AUTOSAR XML (schema 4.0)
package /S02CONN/If
  sender receiver interface RemoteSvc
    data val
  sender receiver interface UdsDiag
    data val
package /S02CONN/Swc
  application sw component type TelematicsUnit
    provide port tcuToGwOut: provided-interface=RemoteSvc
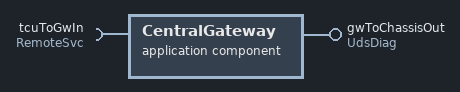
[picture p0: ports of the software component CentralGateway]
  application sw component type CentralGateway
    provide port gwToChassisOut: provided-interface=UdsDiag
    require port tcuToGwIn: required-interface=RemoteSvc
  application sw component type ChassisCtrl
    require port gwToChassisIn: required-interface=UdsDiag
  composition sw component type Root
    component tcu: type=TelematicsUnit
    component cgw: type=CentralGateway
    component chassis: type=ChassisCtrl
    connect tcu.tcuToGwOut -> cgw.tcuToGwIn
    connect cgw.gwToChassisOut -> chassis.gwToChassisIn
package /S02CONN/Comm
  pdu tcuToGwIPdu
    signal tcuToGwISig: system signal tcuToGwSSig
  secured i pdu tcuToGwSecuredIPdu: auth-info-tx-length=32, freshness-value-id=1, freshness-value-length=8, payload=tcuToGwIPdu
  pdu gwToChassisIPdu
    signal gwToChassisISig: system signal gwToChassisSSig
package /S02CONN/Topology
  ecu instance ChassisEcu
  ecu instance GatewayEcu
  ecu instance TcuEcu
  system Veh
    root-software-compositions:
      root sw composition prototype Root: software-composition=Root
    system mapping Map
      data-mappings:
        data-element=Root.tcuToGwOut.val, system-signal=tcuToGwSSig
        data-element=Root.gwToChassisOut.val, system-signal=gwToChassisSSig
      sw-mappings:
        swc to ecu mapping ToChassisEcu: component=chassis, ecu-instance=ChassisEcu
        swc to ecu mapping ToGatewayEcu: component=cgw, ecu-instance=GatewayEcu
        swc to ecu mapping ToTcuEcu: component=tcu, ecu-instance=TcuEcu
